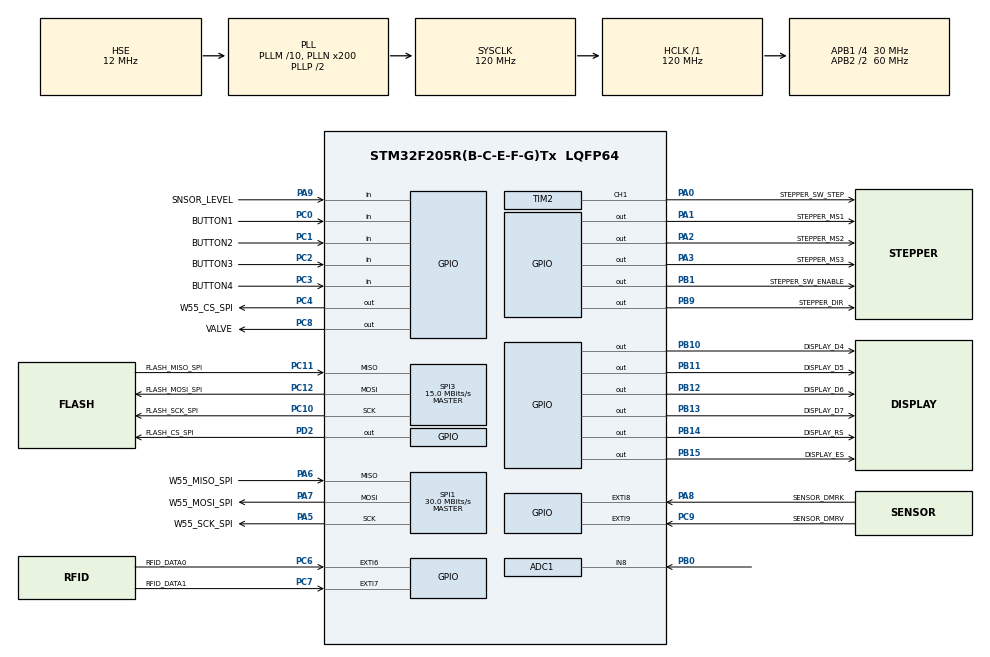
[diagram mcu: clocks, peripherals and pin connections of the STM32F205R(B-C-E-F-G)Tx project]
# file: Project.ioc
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ADC1.Channel-0\#ChannelRegularConversion=ADC_CHANNEL_8
ADC1.ContinuousConvMode=ENABLE
ADC1.DMAContinuousRequests=ENABLE
ADC1.NbrOfConversionFlag=1
ADC1.Rank-0\#ChannelRegularConversion=1
ADC1.SamplingTime-0\#ChannelRegularConversion=ADC_SAMPLETIME_3CYCLES
ADC1.ScanConvMode=ENABLE
ADC1.master=1
Dma.ADC1.4.Direction=DMA_PERIPH_TO_MEMORY
Dma.ADC1.4.FIFOMode=DMA_FIFOMODE_DISABLE
Dma.ADC1.4.Instance=DMA2_Stream4
Dma.ADC1.4.MemDataAlignment=DMA_MDATAALIGN_HALFWORD
Dma.ADC1.4.MemInc=DMA_MINC_ENABLE
Dma.ADC1.4.Mode=DMA_NORMAL
Dma.ADC1.4.PeriphDataAlignment=DMA_PDATAALIGN_HALFWORD
Dma.ADC1.4.PeriphInc=DMA_PINC_DISABLE
Dma.ADC1.4.Priority=DMA_PRIORITY_LOW
Dma.Request0=SPI1_RX
Dma.Request1=SPI1_TX
Dma.Request2=SPI3_RX
Dma.Request3=SPI3_TX
Dma.Request4=ADC1
Dma.SPI1_RX.0.Direction=DMA_PERIPH_TO_MEMORY
Dma.SPI1_RX.0.FIFOMode=DMA_FIFOMODE_DISABLE
Dma.SPI1_RX.0.Instance=DMA2_Stream0
Dma.SPI1_RX.0.MemDataAlignment=DMA_MDATAALIGN_BYTE
Dma.SPI1_RX.0.MemInc=DMA_MINC_ENABLE
Dma.SPI1_RX.0.Mode=DMA_NORMAL
Dma.SPI1_RX.0.PeriphDataAlignment=DMA_PDATAALIGN_BYTE
Dma.SPI1_RX.0.PeriphInc=DMA_PINC_DISABLE
Dma.SPI1_RX.0.Priority=DMA_PRIORITY_LOW
Dma.SPI1_TX.1.Direction=DMA_MEMORY_TO_PERIPH
Dma.SPI1_TX.1.FIFOMode=DMA_FIFOMODE_DISABLE
Dma.SPI1_TX.1.Instance=DMA2_Stream3
Dma.SPI1_TX.1.MemDataAlignment=DMA_MDATAALIGN_BYTE
Dma.SPI1_TX.1.MemInc=DMA_MINC_ENABLE
Dma.SPI1_TX.1.Mode=DMA_NORMAL
Dma.SPI1_TX.1.PeriphDataAlignment=DMA_PDATAALIGN_BYTE
Dma.SPI1_TX.1.PeriphInc=DMA_PINC_DISABLE
Dma.SPI1_TX.1.Priority=DMA_PRIORITY_LOW
Dma.SPI3_RX.2.Direction=DMA_PERIPH_TO_MEMORY
Dma.SPI3_RX.2.FIFOMode=DMA_FIFOMODE_DISABLE
Dma.SPI3_RX.2.Instance=DMA1_Stream0
Dma.SPI3_RX.2.MemDataAlignment=DMA_MDATAALIGN_BYTE
Dma.SPI3_RX.2.MemInc=DMA_MINC_ENABLE
Dma.SPI3_RX.2.Mode=DMA_NORMAL
Dma.SPI3_RX.2.PeriphDataAlignment=DMA_PDATAALIGN_BYTE
Dma.SPI3_RX.2.PeriphInc=DMA_PINC_DISABLE
Dma.SPI3_RX.2.Priority=DMA_PRIORITY_LOW
Dma.SPI3_TX.3.Direction=DMA_MEMORY_TO_PERIPH
Dma.SPI3_TX.3.FIFOMode=DMA_FIFOMODE_DISABLE
Dma.SPI3_TX.3.Instance=DMA1_Stream5
Dma.SPI3_TX.3.MemDataAlignment=DMA_MDATAALIGN_BYTE
Dma.SPI3_TX.3.MemInc=DMA_MINC_ENABLE
Dma.SPI3_TX.3.Mode=DMA_NORMAL
Dma.SPI3_TX.3.PeriphDataAlignment=DMA_PDATAALIGN_BYTE
Dma.SPI3_TX.3.PeriphInc=DMA_PINC_DISABLE
Dma.SPI3_TX.3.Priority=DMA_PRIORITY_LOW
Mcu.Family=STM32F2
Mcu.Name=STM32F205R(B-C-E-F-G)Tx
Mcu.Package=LQFP64
NVIC.DMA1_Stream0_IRQn=true\:0\:0\:false\:false\:true\:false\:true\:true
NVIC.DMA1_Stream5_IRQn=true\:0\:0\:false\:false\:true\:false\:true\:true
NVIC.DMA2_Stream0_IRQn=true\:0\:0\:false\:false\:true\:false\:true\:true
NVIC.DMA2_Stream3_IRQn=true\:0\:0\:false\:false\:true\:false\:true\:true
NVIC.DMA2_Stream4_IRQn=true\:0\:0\:false\:false\:true\:false\:true\:true
NVIC.EXTI9_5_IRQn=true\:0\:0\:false\:false\:true\:true\:true\:true
NVIC.PriorityGroup=NVIC_PRIORITYGROUP_4
NVIC.TIM2_IRQn=true\:0\:0\:false\:false\:true\:true\:true\:true
NVIC.TIM6_DAC_IRQn=true\:0\:0\:false\:false\:true\:false\:true\:true
NVIC.TimeBase=TIM6_DAC_IRQn
NVIC.TimeBaseIP=TIM6
PA0-WKUP.GPIO_Label=STEPPER_SW_STEP
PA0-WKUP.Signal=S_TIM2_CH1_ETR
PA1.GPIO_Label=STEPPER_MS1
PA1.Signal=GPIO_Output
PA13.Mode=Serial_Wire
PA13.Signal=SYS_JTMS-SWDIO
PA14.Mode=Serial_Wire
PA14.Signal=SYS_JTCK-SWCLK
PA2.GPIO_Label=STEPPER_MS2
PA2.Signal=GPIO_Output
PA3.GPIO_Label=STEPPER_MS3
PA3.Signal=GPIO_Output
PA5.GPIO_Label=W55_SCK_SPI
PA5.Mode=Full_Duplex_Master
PA5.Signal=SPI1_SCK
PA6.GPIO_Label=W55_MISO_SPI
PA6.Mode=Full_Duplex_Master
PA6.Signal=SPI1_MISO
PA7.GPIO_Label=W55_MOSI_SPI
PA7.Mode=Full_Duplex_Master
PA7.Signal=SPI1_MOSI
PA8.GPIO_Label=SENSOR_DMRK
PA8.Signal=GPXTI8
PA9.GPIO_Label=SNSOR_LEVEL
PA9.Signal=GPIO_Input
PB0.Signal=ADCx_IN8
PB1.GPIO_Label=STEPPER_SW_ENABLE
PB1.Signal=GPIO_Output
PB10.GPIO_Label=DISPLAY_D4
PB10.Signal=GPIO_Output
PB11.GPIO_Label=DISPLAY_D5
PB11.Signal=GPIO_Output
PB12.GPIO_Label=DISPLAY_D6
PB12.Signal=GPIO_Output
PB13.GPIO_Label=DISPLAY_D7
PB13.Signal=GPIO_Output
PB14.GPIO_Label=DISPLAY_RS
PB14.Signal=GPIO_Output
PB15.GPIO_Label=DISPLAY_ES
PB15.Signal=GPIO_Output
PB9.GPIO_Label=STEPPER_DIR
PB9.Signal=GPIO_Output
PC0.GPIO_Label=BUTTON1
PC0.Signal=GPIO_Input
PC1.GPIO_Label=BUTTON2
PC1.Signal=GPIO_Input
PC10.GPIO_Label=FLASH_SCK_SPI
PC10.Mode=Full_Duplex_Master
PC10.Signal=SPI3_SCK
PC11.GPIO_Label=FLASH_MISO_SPI
PC11.Mode=Full_Duplex_Master
PC11.Signal=SPI3_MISO
PC12.GPIO_Label=FLASH_MOSI_SPI
PC12.Mode=Full_Duplex_Master
PC12.Signal=SPI3_MOSI
PC13.Signal=RTC_AF1
PC14-OSC32_IN.Mode=LSE-External-Oscillator
PC14-OSC32_IN.Signal=RCC_OSC32_IN
PC15-OSC32_OUT.Mode=LSE-External-Oscillator
PC15-OSC32_OUT.Signal=RCC_OSC32_OUT
PC2.GPIO_Label=BUTTON3
PC2.Signal=GPIO_Input
PC3.GPIO_Label=BUTTON4
PC3.Signal=GPIO_Input
PC4.GPIO_Label=W55_CS_SPI
PC4.Signal=GPIO_Output
PC6.GPIO_Label=RFID_DATA0
PC6.Signal=GPXTI6
PC7.GPIO_Label=RFID_DATA1
PC7.Signal=GPXTI7
PC8.GPIO_Label=VALVE
PC8.GPIO_Speed=GPIO_SPEED_FREQ_MEDIUM
PC8.PinState=GPIO_PIN_SET
PC8.Signal=GPIO_Output
PC9.GPIO_Label=SENSOR_DMRV
PC9.GPIO_ModeDefaultEXTI=GPIO_MODE_IT_RISING
PC9.Signal=GPXTI9
PD2.GPIO_Label=FLASH_CS_SPI
PD2.Signal=GPIO_Output
PH0-OSC_IN.Mode=HSE-External-Oscillator
PH0-OSC_IN.Signal=RCC_OSC_IN
PH1-OSC_OUT.Mode=HSE-External-Oscillator
PH1-OSC_OUT.Signal=RCC_OSC_OUT
ProjectManager.HeapSize=0x200
ProjectManager.StackSize=0x400
ProjectManager.TargetToolchain=EWARM V8.32
RCC.48MHZClocksFreq_Value=60000000
RCC.AHBFreq_Value=120000000
RCC.APB1CLKDivider=RCC_HCLK_DIV4
RCC.APB1Freq_Value=30000000
RCC.APB1TimFreq_Value=60000000
RCC.APB2CLKDivider=RCC_HCLK_DIV2
RCC.APB2Freq_Value=60000000
RCC.APB2TimFreq_Value=120000000
RCC.CortexFreq_Value=120000000
RCC.HCLKFreq_Value=120000000
RCC.HSE_VALUE=12000000
RCC.HSI_VALUE=16000000
RCC.PLLM=10
RCC.PLLN=200
RCC.PLLSourceVirtual=RCC_PLLSOURCE_HSE
RCC.RCC_RTC_Clock_SourceVirtual=RCC_RTCCLKSOURCE_LSE
RCC.SYSCLKFreq_VALUE=120000000
RCC.SYSCLKSource=RCC_SYSCLKSOURCE_PLLCLK
RCC.VCOOutputFreq_Value=240000000
SH.ADCx_IN8.0=ADC1_IN8,IN8
SH.S_TIM2_CH1_ETR.0=TIM2_CH1,PWM Generation1 CH1
SPI1.BaudRatePrescaler=SPI_BAUDRATEPRESCALER_2
SPI1.CalculateBaudRate=30.0 MBits/s
SPI1.Direction=SPI_DIRECTION_2LINES
SPI1.Mode=SPI_MODE_MASTER
SPI1.VirtualType=VM_MASTER
SPI3.BaudRatePrescaler=SPI_BAUDRATEPRESCALER_2
SPI3.CalculateBaudRate=15.0 MBits/s
SPI3.Direction=SPI_DIRECTION_2LINES
SPI3.Mode=SPI_MODE_MASTER
SPI3.VirtualType=VM_MASTER
TIM2.AutoReloadPreload=TIM_AUTORELOAD_PRELOAD_ENABLE
TIM2.Channel-PWM\ Generation1\ CH1=TIM_CHANNEL_1
TIM2.OCMode_PWM-PWM\ Generation1\ CH1=TIM_OCMODE_PWM2
TIM2.OCPolarity_1=TIM_OCPOLARITY_LOW
TIM2.Period=1000
TIM2.Prescaler=120
TIM2.Pulse-PWM\ Generation1\ CH1=500
VP_SYS_VS_tim6.Mode=TIM6
board=custom

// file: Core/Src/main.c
/* USER CODE BEGIN Header */
/**
  ******************************************************************************
  * @file           : main.c
  * @brief          : Main program body
  ******************************************************************************
  * @attention
  *
  * <h2><center>&copy; Copyright (c) 2020 STMicroelectronics.
  * All rights reserved.</center></h2>
  *
  * This software component is licensed by ST under BSD 3-Clause license,
  * the "License"; You may not use this file except in compliance with the
  * License. You may obtain a copy of the License at:
  *                        opensource.org/licenses/BSD-3-Clause
  *
  ******************************************************************************
  */
/* USER CODE END Header */
#include "main.h"
#include "adc.h"
#include "dma.h"
#include "spi.h"
#include "tim.h"
#include "gpio.h"

/* USER CODE BEGIN Includes */
#include "modules/Startup.h"
/* USER CODE END Includes */

void SystemClock_Config(void);

int main(void)
{

  /* MCU Configuration--------------------------------------------------------*/

  /* Reset of all peripherals, Initializes the Flash interface and the Systick. */
  HAL_Init();

  /* Configure the system clock */
  SystemClock_Config();

  /* Initialize all configured peripherals */
  MX_GPIO_Init();
  MX_DMA_Init();
  MX_SPI1_Init();
  MX_SPI3_Init();
  MX_TIM2_Init();
  MX_ADC1_Init();
  /* USER CODE BEGIN 2 */
  startup();
  /* USER CODE END 2 */

  /* Infinite loop */
  while (1)
  {

  }
}

void SystemClock_Config(void)
{
  RCC_OscInitTypeDef RCC_OscInitStruct = {0};
  RCC_ClkInitTypeDef RCC_ClkInitStruct = {0};
  RCC_PeriphCLKInitTypeDef PeriphClkInitStruct = {0};

  /** Initializes the RCC Oscillators according to the specified parameters
  * in the RCC_OscInitTypeDef structure.
  */
  RCC_OscInitStruct.OscillatorType = RCC_OSCILLATORTYPE_HSE|RCC_OSCILLATORTYPE_LSE;
  RCC_OscInitStruct.HSEState = RCC_HSE_ON;
  RCC_OscInitStruct.LSEState = RCC_LSE_ON;
  RCC_OscInitStruct.PLL.PLLState = RCC_PLL_ON;
  RCC_OscInitStruct.PLL.PLLSource = RCC_PLLSOURCE_HSE;
  RCC_OscInitStruct.PLL.PLLM = 10;
  RCC_OscInitStruct.PLL.PLLN = 200;
  RCC_OscInitStruct.PLL.PLLP = RCC_PLLP_DIV2;
  RCC_OscInitStruct.PLL.PLLQ = 4;
  if (HAL_RCC_OscConfig(&RCC_OscInitStruct) != HAL_OK)
  {
    Error_Handler();
  }
  /** Initializes the CPU, AHB and APB buses clocks
  */
  RCC_ClkInitStruct.ClockType = RCC_CLOCKTYPE_HCLK|RCC_CLOCKTYPE_SYSCLK
                              |RCC_CLOCKTYPE_PCLK1|RCC_CLOCKTYPE_PCLK2;
  RCC_ClkInitStruct.SYSCLKSource = RCC_SYSCLKSOURCE_PLLCLK;
  RCC_ClkInitStruct.AHBCLKDivider = RCC_SYSCLK_DIV1;
  RCC_ClkInitStruct.APB1CLKDivider = RCC_HCLK_DIV4;
  RCC_ClkInitStruct.APB2CLKDivider = RCC_HCLK_DIV2;

  if (HAL_RCC_ClockConfig(&RCC_ClkInitStruct, FLASH_LATENCY_3) != HAL_OK)
  {
    Error_Handler();
  }
  PeriphClkInitStruct.PeriphClockSelection = RCC_PERIPHCLK_RTC;
  PeriphClkInitStruct.RTCClockSelection = RCC_RTCCLKSOURCE_LSE;
  if (HAL_RCCEx_PeriphCLKConfig(&PeriphClkInitStruct) != HAL_OK)
  {
    Error_Handler();
  }
}

/* USER CODE BEGIN 4 */

//COPY OF RCC INITIALIZATION FUNCTION
///**
//  * @brief System Clock Configuration
//  * @retval None
//  */
//void SystemClock_Config(void)
//{
//  RCC_OscInitTypeDef RCC_OscInitStruct = {0};
//  RCC_ClkInitTypeDef RCC_ClkInitStruct = {0};
//  RCC_PeriphCLKInitTypeDef PeriphClkInitStruct = {0};
//
//  /** Initializes the RCC Oscillators according to the specified parameters
//  * in the RCC_OscInitTypeDef structure.
//  */
//  RCC_OscInitStruct.OscillatorType = RCC_OSCILLATORTYPE_HSE|RCC_OSCILLATORTYPE_LSE;
//  RCC_OscInitStruct.HSEState = RCC_HSE_ON;
//  RCC_OscInitStruct.LSEState = RCC_LSE_ON;
//  RCC_OscInitStruct.PLL.PLLState = RCC_PLL_ON;
//  RCC_OscInitStruct.PLL.PLLSource = RCC_PLLSOURCE_HSE;
//  RCC_OscInitStruct.PLL.PLLM = 10;
//  RCC_OscInitStruct.PLL.PLLN = 200;
//  RCC_OscInitStruct.PLL.PLLP = RCC_PLLP_DIV2;
//  RCC_OscInitStruct.PLL.PLLQ = 4;
//  if (HAL_RCC_OscConfig(&RCC_OscInitStruct) != HAL_OK)
//  {
//    Error_Handler();
//  }
//  /** Initializes the CPU, AHB and APB buses clocks
//  */
//  RCC_ClkInitStruct.ClockType = RCC_CLOCKTYPE_HCLK|RCC_CLOCKTYPE_SYSCLK
//                              |RCC_CLOCKTYPE_PCLK1|RCC_CLOCKTYPE_PCLK2;
//  RCC_ClkInitStruct.SYSCLKSource = RCC_SYSCLKSOURCE_PLLCLK;
//  RCC_ClkInitStruct.AHBCLKDivider = RCC_SYSCLK_DIV1;
//  RCC_ClkInitStruct.APB1CLKDivider = RCC_HCLK_DIV4;
//  RCC_ClkInitStruct.APB2CLKDivider = RCC_HCLK_DIV2;
//
//  if (HAL_RCC_ClockConfig(&RCC_ClkInitStruct, FLASH_LATENCY_3) != HAL_OK)
//  {
//    Error_Handler();
//  }
//  PeriphClkInitStruct.PeriphClockSelection = RCC_PERIPHCLK_RTC;
//  PeriphClkInitStruct.RTCClockSelection = RCC_RTCCLKSOURCE_LSE;
//  if (HAL_RCCEx_PeriphCLKConfig(&PeriphClkInitStruct) != HAL_OK)
//  {
//    Error_Handler();
//  }
//}

/* USER CODE END 4 */

void HAL_TIM_PeriodElapsedCallback(TIM_HandleTypeDef *htim)
{
  if (htim->Instance == TIM6) {
    HAL_IncTick();
  }
}

void Error_Handler(void)
{
}

/************************ (C) COPYRIGHT STMicroelectronics *****END OF FILE****/
